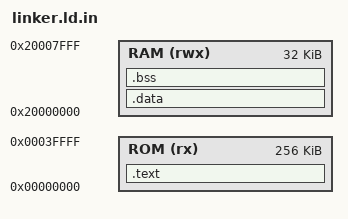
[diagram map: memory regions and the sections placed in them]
ENTRY(Reset_Handler)

MEMORY
{
  ROM (rx)  : ORIGIN = 0x00000000, LENGTH = 0x00040000 /* 256K */
  RAM (rwx) : ORIGIN = 0x20000000, LENGTH = 0x00008000 /* 32K */
}

SECTIONS
{
  .text :
  {
    . = ALIGN(4);
    KEEP(*(.isr_vector))
    . = ALIGN(4);
    *(.text*)
    *(.rodata*)
    . = ALIGN(4);
  } > ROM

  .data : AT(ADDR(.text) + SIZEOF(.text))
  {
    . = ALIGN(4);
    _sdata = .;
    _ldata = LOADADDR (.data);
    *(.data*)
    . = ALIGN(4);
    _edata = .;
  } > RAM

  .bss :
  {
    . = ALIGN(4);
    _sbss = .;
    *(.bss*)
    *(COMMON)
    . = ALIGN(4);
    _ebss = .;
  } > RAM
}
